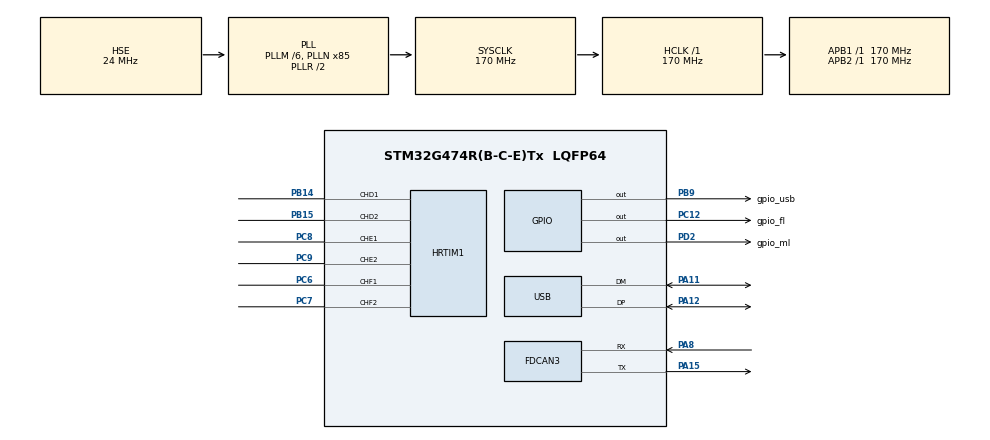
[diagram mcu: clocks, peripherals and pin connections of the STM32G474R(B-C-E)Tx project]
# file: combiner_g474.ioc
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Mcu.Family=STM32G4
RCC.CortexFreq_Value=170000000
PC12.Signal=GPIO_Output
PA14.GPIO_Label=T_SWCLK
NVIC.RTC_WKUP_IRQn=true\:0\:0\:false\:false\:true\:true\:true
NVIC.USB_HP_IRQn=true\:0\:0\:false\:false\:true\:true\:true
VP_RTC_VS_RTC_Activate.Mode=RTC_Enabled
NVIC.FDCAN3_IT0_IRQn=true\:0\:0\:false\:false\:true\:true\:true
PA11.Mode=Device
PD2.GPIO_Speed=GPIO_SPEED_FREQ_VERY_HIGH
PB15.Signal=HRTIM1_CHD2
HRTIM1.OCPulse_TD1=hrperiod/2
RCC.SYSCLKSource=RCC_SYSCLKSOURCE_PLLCLK
ProjectManager.StackSize=0x4000
HRTIM1.UpDownMode-Output_TF1TF2=HRTIM_TIMERUPDOWNMODE_UPDOWN
RTC.WakeUpClock-WakeUp=RTC_WAKEUPCLOCK_CK_SPRE_16BITS
PA12.Signal=USB_DP
Mcu.UserConstants=hrperiod,27200*2;main_loop_period,170e6/10000
RCC.HCLKFreq_Value=170000000
RCC.APB2TimFreq_Value=170000000
PC7.Signal=HRTIM1_CHF2
RCC.ADC345CLockSelection=RCC_ADC345CLKSOURCE_PLL
HRTIM1.ORingUpdateSource_ADCTrigger5=HRTIM_ADCTRIGGERUPDATE_TIMER_F
RCC.AHBFreq_Value=170000000
RCC.PREFETCH_ENABLE=1
HRTIM1.ORingUpdateSource_ADCTrigger1=HRTIM_ADCTRIGGERUPDATE_TIMER_F
RCC.HSE_VALUE=24000000
PA15.Mode=FDCANFD
RCC.ADC12Freq_Value=56666666.666666664
RCC.RTCClockSelection=RCC_RTCCLKSOURCE_LSE
HRTIM1.OCMode_TE1=HRTIM_BASICOCMODE_ACTIVE
HRTIM1.EnableCalibration=DLLSimpleCalibration
PC14-OSC32_IN.Mode=LSE-External-Oscillator
PB14.Mode=Output_TD1TD2
PC9.Mode=Output_TE1TE2
VP_SYS_VS_DBSignals.Mode=DisableDeadBatterySignals
HRTIM1.Source_ADCTrigger5=HRTIM_ADCTRIGGEREVENT579_TIMERF_PERIOD
PA8.Signal=FDCAN3_RX
HRTIM1.OCMode_TF1=HRTIM_BASICOCMODE_ACTIVE
HRTIM1.OCMode_TF2=HRTIM_BASICOCMODE_INACTIVE
HRTIM1.OCPolarity_TD1=HRTIM_OUTPUTPOLARITY_HIGH
PB9.Signal=GPIO_Output
Mcu.Package=LQFP64
VP_RCC_VS_USB.Mode=USB_FS
HRTIM1.OCPolarity_TE1=HRTIM_OUTPUTPOLARITY_HIGH
RTC.WakeUpCounter-WakeUp=1
VP_RTC_VS_RTC_Calendar.Mode=RTC_Calendar
PA15.Signal=FDCAN3_TX
HRTIM1.ADCTrigger1_Source1=HRTIM_ADCTRIGGEREVENT13_TIMERF_RESET
NVIC.USB_LP_IRQn=true\:0\:0\:false\:false\:true\:true\:true
HRTIM1.NumberADCTriggerSource2=1
HRTIM1.NumberADCTriggerSource1=1
PB9.GPIO_Speed=GPIO_SPEED_FREQ_VERY_HIGH
RCC.APB1TimFreq_Value=170000000
HRTIM1.OCMode_TD1=HRTIM_BASICOCMODE_ACTIVE
RCC.CK48CLockSelection=RCC_USBCLKSOURCE_HSI48
PF1-OSC_OUT.Mode=HSE-External-Oscillator
HRTIM1.UpDownMode-Output_TE1TE2=HRTIM_TIMERUPDOWNMODE_UPDOWN
HRTIM1.OCPolarity_TF1=HRTIM_OUTPUTPOLARITY_HIGH
PF1-OSC_OUT.Signal=RCC_OSC_OUT
RCC.HSI48_VALUE=48000000
HRTIM1.ADCTrigger_Id7=__NULL
RCC.PLLSourceVirtual=RCC_PLLSOURCE_HSE
PC15-OSC32_OUT.Mode=LSE-External-Oscillator
PB9.GPIO_Label=gpio_usb
HRTIM1.UpDownMode-Output_TD1TD2=HRTIM_TIMERUPDOWNMODE_UPDOWN
HRTIM1.ADCTrigger2_Source1=HRTIM_ADCTRIGGEREVENT24_TIMERF_PERIOD
PC8.Signal=HRTIM1_CHE1
PC6.Signal=HRTIM1_CHF1
RCC.EXTERNAL_CLOCK_VALUE=12288000
PC14-OSC32_IN.Signal=RCC_OSC32_IN
HRTIM1.PrescalerRatio_TF=HRTIM_PRESCALERRATIO_MUL32
PA13.Signal=SYS_JTMS-SWDIO
PC12.PinState=GPIO_PIN_RESET
ProjectManager.TargetToolchain=Makefile
PC6.Mode=Output_TF1TF2
RCC.USBFreq_Value=48000000
PC15-OSC32_OUT.Signal=RCC_OSC32_OUT
HRTIM1.Adrom_TF=HRTIM_TIM_ADROM_VALLEY
PF0-OSC_IN.Mode=HSE-External-Oscillator
PB14.Signal=HRTIM1_CHD1
HRTIM1.ADCTrigger_Id2=__NULL
HRTIM1.ADCTrigger_Id1=HRTIM_ADCTRIGGER_1
HRTIM1.ADCTrigger_Id3=__NULL
HRTIM1.ADCTrigger_Id6=__NULL
board=NUCLEO-G474RE
HRTIM1.ADCTrigger_Id5=HRTIM_ADCTRIGGER_5
NVIC.HRTIM1_Master_IRQn=true\:0\:0\:false\:false\:true\:false\:true
RCC.VCOOutputFreq_Value=340000000
PB15.Mode=Output_TD1TD2
RCC.ADC345Freq_Value=56666666.666666664
RCC.APB2Freq_Value=170000000
HRTIM1.OCChannel_TE1=HRTIM_OUTPUT_TE1
HRTIM1.PWMChannel_TF2=__NULL
HRTIM1.PWMChannel_TF1=__NULL
HRTIM1.postscaler5=0
Mcu.Name=STM32G474R(B-C-E)Tx
PA13.GPIO_Label=T_SWDIO
HRTIM1.OCChannel_TF1=HRTIM_OUTPUT_TF1
PC8.Mode=Output_TE1TE2
HRTIM1.OCChannel_TF2=__NULL
RCC.SYSCLKFreq_VALUE=170000000
PA12.Mode=Device
RCC.ADC12CLockSelection=RCC_ADC12CLKSOURCE_PLL
PC12.GPIO_Label=gpio_fl
PA11.Signal=USB_DM
PA14.Signal=SYS_JTCK-SWCLK
ProjectManager.HeapSize=0x2000
RCC.HSI_VALUE=16000000
VP_RTC_VS_RTC_WakeUp_intern.Mode=WakeUp
RCC.PLLP=RCC_PLLP_DIV6
RCC.PLLQ=RCC_PLLQ_DIV8
NVIC.PriorityGroup=NVIC_PRIORITYGROUP_4
HRTIM1.OCPulse_TE1=hrperiod/2
RCC.PLLM=RCC_PLLM_DIV6
RCC.PLLN=85
PA8.Mode=FDCANFD
PC9.Signal=HRTIM1_CHE2
HRTIM1.Configuration_TF=Simple
PF0-OSC_IN.Signal=RCC_OSC_IN
HRTIM1.Configuration_TD=Simple
PC7.Mode=Output_TF1TF2
HRTIM1.Configuration_TE=Simple
PD2.Signal=GPIO_Output
RCC.APB1Freq_Value=170000000
PC12.GPIO_Speed=GPIO_SPEED_FREQ_VERY_HIGH
HRTIM1.OCChannel_TD1=HRTIM_OUTPUT_TD1
HRTIM1.Periode_TD=hrperiod
PD2.GPIO_Label=gpio_ml
HRTIM1.Periode_TE=hrperiod
HRTIM1.Periode_TF=hrperiod
HRTIM1.OCPulse_TF1=hrperiod/2
HRTIM1.OCPulse_TF2=4000

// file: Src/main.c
/* USER CODE BEGIN Header */
/**
  ******************************************************************************
  * @file           : main.c
  * @brief          : Main program body
  ******************************************************************************
  * @attention
  *
  * <h2><center>&copy; Copyright (c) 2020 STMicroelectronics.
  * All rights reserved.</center></h2>
  *
  * This software component is licensed by ST under BSD 3-Clause license,
  * the "License"; You may not use this file except in compliance with the
  * License. You may obtain a copy of the License at:
  *                        opensource.org/licenses/BSD-3-Clause
  *
  ******************************************************************************
  */
/* USER CODE END Header */

#include "main.h"

FDCAN_HandleTypeDef hfdcan3;

HRTIM_HandleTypeDef hhrtim1;

RTC_HandleTypeDef hrtc;

PCD_HandleTypeDef hpcd_USB_FS;

void SystemClock_Config(void);
static void MX_GPIO_Init(void);
static void MX_HRTIM1_Init(void);
static void MX_USB_PCD_Init(void);
static void MX_FDCAN3_Init(void);
static void MX_RTC_Init(void);

int main(void)
{

  /* MCU Configuration--------------------------------------------------------*/

  /* Reset of all peripherals, Initializes the Flash interface and the Systick. */
  HAL_Init();

  /* Configure the system clock */
  SystemClock_Config();

  /* Initialize all configured peripherals */
  MX_GPIO_Init();
  MX_HRTIM1_Init();
  MX_USB_PCD_Init();
  MX_FDCAN3_Init();
  MX_RTC_Init();
  /* USER CODE BEGIN 2 */
  //Hal_can
  /* USER CODE END 2 */

  /* Infinite loop */
  while (1)
  {

  }
}

void SystemClock_Config(void)
{
  RCC_OscInitTypeDef RCC_OscInitStruct = {0};
  RCC_ClkInitTypeDef RCC_ClkInitStruct = {0};
  RCC_PeriphCLKInitTypeDef PeriphClkInit = {0};
  RCC_CRSInitTypeDef pInit = {0};

  /** Configure the main internal regulator output voltage
  */
  HAL_PWREx_ControlVoltageScaling(PWR_REGULATOR_VOLTAGE_SCALE1_BOOST);
  /** Configure LSE Drive Capability
  */
  HAL_PWR_EnableBkUpAccess();
  __HAL_RCC_LSEDRIVE_CONFIG(RCC_LSEDRIVE_LOW);
  /** Initializes the CPU, AHB and APB busses clocks
  */
  RCC_OscInitStruct.OscillatorType = RCC_OSCILLATORTYPE_HSI48|RCC_OSCILLATORTYPE_HSE
                              |RCC_OSCILLATORTYPE_LSE;
  RCC_OscInitStruct.HSEState = RCC_HSE_ON;
  RCC_OscInitStruct.LSEState = RCC_LSE_ON;
  RCC_OscInitStruct.HSI48State = RCC_HSI48_ON;
  RCC_OscInitStruct.PLL.PLLState = RCC_PLL_ON;
  RCC_OscInitStruct.PLL.PLLSource = RCC_PLLSOURCE_HSE;
  RCC_OscInitStruct.PLL.PLLM = RCC_PLLM_DIV6;
  RCC_OscInitStruct.PLL.PLLN = 85;
  RCC_OscInitStruct.PLL.PLLP = RCC_PLLP_DIV6;
  RCC_OscInitStruct.PLL.PLLQ = RCC_PLLQ_DIV8;
  RCC_OscInitStruct.PLL.PLLR = RCC_PLLR_DIV2;
  if (HAL_RCC_OscConfig(&RCC_OscInitStruct) != HAL_OK)
  {
    Error_Handler();
  }
  /** Initializes the CPU, AHB and APB busses clocks
  */
  RCC_ClkInitStruct.ClockType = RCC_CLOCKTYPE_HCLK|RCC_CLOCKTYPE_SYSCLK
                              |RCC_CLOCKTYPE_PCLK1|RCC_CLOCKTYPE_PCLK2;
  RCC_ClkInitStruct.SYSCLKSource = RCC_SYSCLKSOURCE_PLLCLK;
  RCC_ClkInitStruct.AHBCLKDivider = RCC_SYSCLK_DIV1;
  RCC_ClkInitStruct.APB1CLKDivider = RCC_HCLK_DIV1;
  RCC_ClkInitStruct.APB2CLKDivider = RCC_HCLK_DIV1;

  if (HAL_RCC_ClockConfig(&RCC_ClkInitStruct, FLASH_LATENCY_8) != HAL_OK)
  {
    Error_Handler();
  }
  /** Initializes the peripherals clocks
  */
  PeriphClkInit.PeriphClockSelection = RCC_PERIPHCLK_RTC|RCC_PERIPHCLK_USB
                              |RCC_PERIPHCLK_FDCAN;
  PeriphClkInit.FdcanClockSelection = RCC_FDCANCLKSOURCE_PCLK1;
  PeriphClkInit.UsbClockSelection = RCC_USBCLKSOURCE_HSI48;
  PeriphClkInit.RTCClockSelection = RCC_RTCCLKSOURCE_LSE;
  if (HAL_RCCEx_PeriphCLKConfig(&PeriphClkInit) != HAL_OK)
  {
    Error_Handler();
  }
  /** Configures CRS
  */
  pInit.Prescaler = RCC_CRS_SYNC_DIV1;
  pInit.Source = RCC_CRS_SYNC_SOURCE_USB;
  pInit.Polarity = RCC_CRS_SYNC_POLARITY_RISING;
  pInit.ReloadValue = __HAL_RCC_CRS_RELOADVALUE_CALCULATE(48000000,1000);
  pInit.ErrorLimitValue = 34;
  pInit.HSI48CalibrationValue = 32;

  HAL_RCCEx_CRSConfig(&pInit);
}

static void MX_FDCAN3_Init(void)
{

  hfdcan3.Instance = FDCAN3;
  hfdcan3.Init.FrameFormat = FDCAN_FRAME_FD_NO_BRS;
  hfdcan3.Init.Mode = FDCAN_MODE_NORMAL;
  hfdcan3.Init.AutoRetransmission = DISABLE;
  hfdcan3.Init.TransmitPause = DISABLE;
  hfdcan3.Init.ProtocolException = DISABLE;
  hfdcan3.Init.NominalPrescaler = 1;
  hfdcan3.Init.NominalSyncJumpWidth = 1;
  hfdcan3.Init.NominalTimeSeg1 = 2;
  hfdcan3.Init.NominalTimeSeg2 = 2;
  hfdcan3.Init.DataPrescaler = 1;
  hfdcan3.Init.DataSyncJumpWidth = 1;
  hfdcan3.Init.DataTimeSeg1 = 1;
  hfdcan3.Init.DataTimeSeg2 = 1;
  hfdcan3.Init.StdFiltersNbr = 0;
  hfdcan3.Init.ExtFiltersNbr = 0;
  hfdcan3.Init.TxFifoQueueMode = FDCAN_TX_FIFO_OPERATION;
  if (HAL_FDCAN_Init(&hfdcan3) != HAL_OK)
  {
    Error_Handler();
  }

}

static void MX_HRTIM1_Init(void)
{

  HRTIM_ADCTriggerCfgTypeDef pADCTriggerCfg = {0};
  HRTIM_TimeBaseCfgTypeDef pTimeBaseCfg = {0};
  HRTIM_TimerCtlTypeDef pTimerCtl = {0};
  HRTIM_SimpleOCChannelCfgTypeDef pSimpleOCChannelCfg = {0};

  hhrtim1.Instance = HRTIM1;
  hhrtim1.Init.HRTIMInterruptResquests = HRTIM_IT_NONE;
  hhrtim1.Init.SyncOptions = HRTIM_SYNCOPTION_NONE;
  if (HAL_HRTIM_Init(&hhrtim1) != HAL_OK)
  {
    Error_Handler();
  }
  if (HAL_HRTIM_DLLCalibrationStart(&hhrtim1, HRTIM_CALIBRATIONRATE_3) != HAL_OK)
  {
    Error_Handler();
  }
  if (HAL_HRTIM_PollForDLLCalibration(&hhrtim1, 10) != HAL_OK)
  {
    Error_Handler();
  }
  pADCTriggerCfg.UpdateSource = HRTIM_ADCTRIGGERUPDATE_TIMER_F;
  pADCTriggerCfg.Trigger = HRTIM_ADCTRIGGEREVENT13_TIMERF_RESET;
  if (HAL_HRTIM_ADCTriggerConfig(&hhrtim1, HRTIM_ADCTRIGGER_1, &pADCTriggerCfg) != HAL_OK)
  {
    Error_Handler();
  }
  if (HAL_HRTIM_ADCPostScalerConfig(&hhrtim1, HRTIM_ADCTRIGGER_1, 0x0) != HAL_OK)
  {
    Error_Handler();
  }
  pADCTriggerCfg.Trigger = HRTIM_ADCTRIGGEREVENT579_TIMERF_PERIOD;
  if (HAL_HRTIM_ADCTriggerConfig(&hhrtim1, HRTIM_ADCTRIGGER_5, &pADCTriggerCfg) != HAL_OK)
  {
    Error_Handler();
  }
  if (HAL_HRTIM_ADCPostScalerConfig(&hhrtim1, HRTIM_ADCTRIGGER_5, 0) != HAL_OK)
  {
    Error_Handler();
  }
  pTimeBaseCfg.Period = hrperiod;
  pTimeBaseCfg.RepetitionCounter = 0x00;
  pTimeBaseCfg.PrescalerRatio = HRTIM_PRESCALERRATIO_MUL32;
  pTimeBaseCfg.Mode = HRTIM_MODE_CONTINUOUS;
  if (HAL_HRTIM_TimeBaseConfig(&hhrtim1, HRTIM_TIMERINDEX_TIMER_D, &pTimeBaseCfg) != HAL_OK)
  {
    Error_Handler();
  }
  pTimerCtl.UpDownMode = HRTIM_TIMERUPDOWNMODE_UPDOWN;
  pTimerCtl.DualChannelDacEnable = HRTIM_TIMER_DCDE_DISABLED;

  if (HAL_HRTIM_WaveformTimerControl(&hhrtim1, HRTIM_TIMERINDEX_TIMER_D, &pTimerCtl) != HAL_OK)
  {
    Error_Handler();
  }
  if (HAL_HRTIM_RollOverModeConfig(&hhrtim1, HRTIM_TIMERINDEX_TIMER_D, HRTIM_TIM_FEROM_BOTH|HRTIM_TIM_BMROM_BOTH
                              |HRTIM_TIM_ADROM_BOTH|HRTIM_TIM_OUTROM_BOTH
                              |HRTIM_TIM_ROM_BOTH) != HAL_OK)
  {
    Error_Handler();
  }
  pSimpleOCChannelCfg.Mode = HRTIM_BASICOCMODE_ACTIVE;
  pSimpleOCChannelCfg.Pulse = hrperiod/2;
  pSimpleOCChannelCfg.Polarity = HRTIM_OUTPUTPOLARITY_HIGH;
  pSimpleOCChannelCfg.IdleLevel = HRTIM_OUTPUTIDLELEVEL_INACTIVE;
  if (HAL_HRTIM_SimpleOCChannelConfig(&hhrtim1, HRTIM_TIMERINDEX_TIMER_D, HRTIM_OUTPUT_TD1, &pSimpleOCChannelCfg) != HAL_OK)
  {
    Error_Handler();
  }
  if (HAL_HRTIM_TimeBaseConfig(&hhrtim1, HRTIM_TIMERINDEX_TIMER_E, &pTimeBaseCfg) != HAL_OK)
  {
    Error_Handler();
  }
  pTimerCtl.DualChannelDacEnable = HRTIM_TIMER_DCDE_DISABLED;

  if (HAL_HRTIM_WaveformTimerControl(&hhrtim1, HRTIM_TIMERINDEX_TIMER_E, &pTimerCtl) != HAL_OK)
  {
    Error_Handler();
  }
  if (HAL_HRTIM_RollOverModeConfig(&hhrtim1, HRTIM_TIMERINDEX_TIMER_E, HRTIM_TIM_FEROM_BOTH|HRTIM_TIM_BMROM_BOTH
                              |HRTIM_TIM_ADROM_BOTH|HRTIM_TIM_OUTROM_BOTH
                              |HRTIM_TIM_ROM_BOTH) != HAL_OK)
  {
    Error_Handler();
  }
  if (HAL_HRTIM_SimpleOCChannelConfig(&hhrtim1, HRTIM_TIMERINDEX_TIMER_E, HRTIM_OUTPUT_TE1, &pSimpleOCChannelCfg) != HAL_OK)
  {
    Error_Handler();
  }
  if (HAL_HRTIM_TimeBaseConfig(&hhrtim1, HRTIM_TIMERINDEX_TIMER_F, &pTimeBaseCfg) != HAL_OK)
  {
    Error_Handler();
  }
  pTimerCtl.DualChannelDacEnable = HRTIM_TIMER_DCDE_DISABLED;

  if (HAL_HRTIM_WaveformTimerControl(&hhrtim1, HRTIM_TIMERINDEX_TIMER_F, &pTimerCtl) != HAL_OK)
  {
    Error_Handler();
  }
  if (HAL_HRTIM_RollOverModeConfig(&hhrtim1, HRTIM_TIMERINDEX_TIMER_F, HRTIM_TIM_FEROM_BOTH|HRTIM_TIM_BMROM_BOTH
                              |HRTIM_TIM_ADROM_VALLEY|HRTIM_TIM_OUTROM_BOTH
                              |HRTIM_TIM_ROM_BOTH) != HAL_OK)
  {
    Error_Handler();
  }
  if (HAL_HRTIM_SimpleOCChannelConfig(&hhrtim1, HRTIM_TIMERINDEX_TIMER_F, HRTIM_OUTPUT_TF1, &pSimpleOCChannelCfg) != HAL_OK)
  {
    Error_Handler();
  }
  HAL_HRTIM_MspPostInit(&hhrtim1);

}

static void MX_RTC_Init(void)
{

  RTC_TimeTypeDef sTime = {0};
  RTC_DateTypeDef sDate = {0};

  /** Initialize RTC Only
  */
  hrtc.Instance = RTC;
  hrtc.Init.HourFormat = RTC_HOURFORMAT_24;
  hrtc.Init.AsynchPrediv = 127;
  hrtc.Init.SynchPrediv = 255;
  hrtc.Init.OutPut = RTC_OUTPUT_DISABLE;
  hrtc.Init.OutPutRemap = RTC_OUTPUT_REMAP_NONE;
  hrtc.Init.OutPutPullUp = RTC_OUTPUT_PULLUP_NONE;
  if (HAL_RTC_Init(&hrtc) != HAL_OK)
  {
    Error_Handler();
  }

  /** Initialize RTC and set the Time and Date
  */
  sTime.Hours = 0x0;
  sTime.Minutes = 0x0;
  sTime.Seconds = 0x0;
  sTime.SubSeconds = 0x0;
  sTime.DayLightSaving = RTC_DAYLIGHTSAVING_NONE;
  sTime.StoreOperation = RTC_STOREOPERATION_RESET;
  if (HAL_RTC_SetTime(&hrtc, &sTime, RTC_FORMAT_BCD) != HAL_OK)
  {
    Error_Handler();
  }
  sDate.WeekDay = RTC_WEEKDAY_MONDAY;
  sDate.Month = RTC_MONTH_JANUARY;
  sDate.Date = 0x1;
  sDate.Year = 0x0;

  if (HAL_RTC_SetDate(&hrtc, &sDate, RTC_FORMAT_BCD) != HAL_OK)
  {
    Error_Handler();
  }
  /** Enable the WakeUp
  */
  if (HAL_RTCEx_SetWakeUpTimer_IT(&hrtc, 1, RTC_WAKEUPCLOCK_CK_SPRE_16BITS) != HAL_OK)
  {
    Error_Handler();
  }

}

static void MX_USB_PCD_Init(void)
{

  hpcd_USB_FS.Instance = USB;
  hpcd_USB_FS.Init.dev_endpoints = 8;
  hpcd_USB_FS.Init.speed = PCD_SPEED_FULL;
  hpcd_USB_FS.Init.phy_itface = PCD_PHY_EMBEDDED;
  hpcd_USB_FS.Init.Sof_enable = DISABLE;
  hpcd_USB_FS.Init.low_power_enable = DISABLE;
  hpcd_USB_FS.Init.lpm_enable = DISABLE;
  hpcd_USB_FS.Init.battery_charging_enable = DISABLE;
  if (HAL_PCD_Init(&hpcd_USB_FS) != HAL_OK)
  {
    Error_Handler();
  }

}

static void MX_GPIO_Init(void)
{
  GPIO_InitTypeDef GPIO_InitStruct = {0};

  /* GPIO Ports Clock Enable */
  __HAL_RCC_GPIOC_CLK_ENABLE();
  __HAL_RCC_GPIOF_CLK_ENABLE();
  __HAL_RCC_GPIOB_CLK_ENABLE();
  __HAL_RCC_GPIOA_CLK_ENABLE();
  __HAL_RCC_GPIOD_CLK_ENABLE();

  /*Configure GPIO pin Output Level */
  HAL_GPIO_WritePin(gpio_fl_GPIO_Port, gpio_fl_Pin, GPIO_PIN_RESET);

  /*Configure GPIO pin Output Level */
  HAL_GPIO_WritePin(gpio_ml_GPIO_Port, gpio_ml_Pin, GPIO_PIN_RESET);

  /*Configure GPIO pin Output Level */
  HAL_GPIO_WritePin(gpio_usb_GPIO_Port, gpio_usb_Pin, GPIO_PIN_RESET);

  /*Configure GPIO pin : gpio_fl_Pin */
  GPIO_InitStruct.Pin = gpio_fl_Pin;
  GPIO_InitStruct.Mode = GPIO_MODE_OUTPUT_PP;
  GPIO_InitStruct.Pull = GPIO_NOPULL;
  GPIO_InitStruct.Speed = GPIO_SPEED_FREQ_VERY_HIGH;
  HAL_GPIO_Init(gpio_fl_GPIO_Port, &GPIO_InitStruct);

  /*Configure GPIO pin : gpio_ml_Pin */
  GPIO_InitStruct.Pin = gpio_ml_Pin;
  GPIO_InitStruct.Mode = GPIO_MODE_OUTPUT_PP;
  GPIO_InitStruct.Pull = GPIO_NOPULL;
  GPIO_InitStruct.Speed = GPIO_SPEED_FREQ_VERY_HIGH;
  HAL_GPIO_Init(gpio_ml_GPIO_Port, &GPIO_InitStruct);

  /*Configure GPIO pin : gpio_usb_Pin */
  GPIO_InitStruct.Pin = gpio_usb_Pin;
  GPIO_InitStruct.Mode = GPIO_MODE_OUTPUT_PP;
  GPIO_InitStruct.Pull = GPIO_NOPULL;
  GPIO_InitStruct.Speed = GPIO_SPEED_FREQ_VERY_HIGH;
  HAL_GPIO_Init(gpio_usb_GPIO_Port, &GPIO_InitStruct);

}

void Error_Handler(void)
{
}

/************************ (C) COPYRIGHT STMicroelectronics *****END OF FILE****/
